VERSION ""

NS_ :

BS_:

BU_: INTERCEPTOR COMMA XXX ECM TCM BCM SHIFTER CLUSTER SRS ABS SAS

BO_ 257 ECM_IMMO: 8 ECM
 SG_ LOCKED : 10|1@0+ (1,0) [0|1] "" XXX
 SG_ UNLOCKED : 11|1@0+ (1,0) [0|1] "" XXX

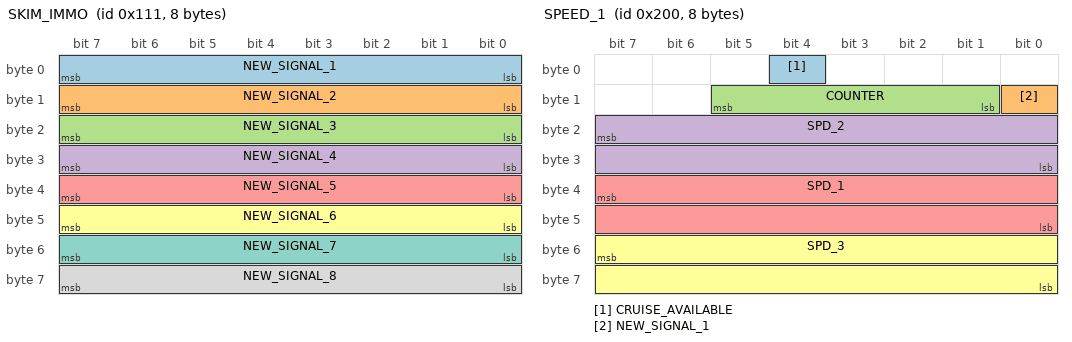
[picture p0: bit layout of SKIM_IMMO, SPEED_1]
BO_ 273 SKIM_IMMO: 8 SKIM
 SG_ NEW_SIGNAL_1 : 7|8@0+ (1,0) [0|255] "" XXX
 SG_ NEW_SIGNAL_2 : 15|8@0+ (1,0) [0|255] "" XXX
 SG_ NEW_SIGNAL_3 : 23|8@0+ (1,0) [0|255] "" XXX
 SG_ NEW_SIGNAL_4 : 31|8@0+ (1,0) [0|255] "" XXX
 SG_ NEW_SIGNAL_5 : 39|8@0+ (1,0) [0|255] "" XXX
 SG_ NEW_SIGNAL_6 : 47|8@0+ (1,0) [0|255] "" XXX
 SG_ NEW_SIGNAL_7 : 55|8@0+ (1,0) [0|255] "" XXX
 SG_ NEW_SIGNAL_8 : 63|8@0+ (1,0) [0|255] "" XXX

BO_ 512 SPEED_1: 8 ABS
 SG_ CRUISE_AVAILABLE : 4|1@0+ (1,0) [0|1] "" XXX
 SG_ NEW_SIGNAL_1 : 8|1@0+ (1,0) [0|1] "" XXX
 SG_ COUNTER : 9|5@1+ (1,0) [0|31] "" XXX
 SG_ SPD_2 : 23|16@0+ (0.059,0) [0|65535] "kph" XXX
 SG_ SPD_1 : 39|16@0+ (0.059,0) [0|65535] "kph" XXX
 SG_ SPD_3 : 55|16@0+ (0.059,0) [0|65535] "kph" XXX

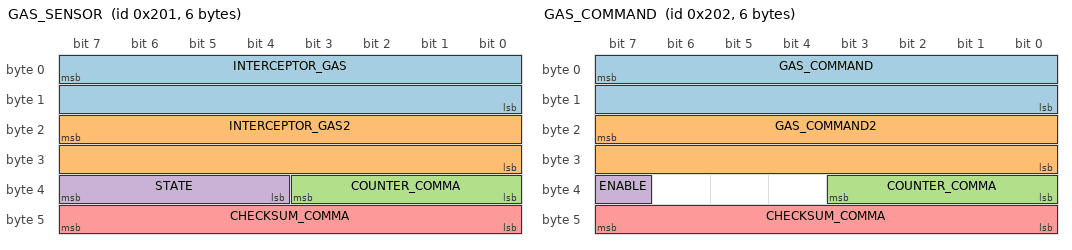
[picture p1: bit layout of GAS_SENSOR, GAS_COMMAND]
BO_ 513 GAS_SENSOR: 6 INTERCEPTOR
 SG_ INTERCEPTOR_GAS : 7|16@0+ (0.098417599,-18.56) [0|1] "" COMMA
 SG_ INTERCEPTOR_GAS2 : 23|16@0+ (0.183585313,-14.79) [0|1] "" COMMA
 SG_ COUNTER_COMMA : 35|4@0+ (1,0) [0|15] "" COMMA
 SG_ STATE : 39|4@0+ (1,0) [0|15] "" COMMA
 SG_ CHECKSUM_COMMA : 47|8@0+ (1,0) [0|255] "" COMMA

BO_ 514 GAS_COMMAND: 6 COMMA
 SG_ GAS_COMMAND : 7|16@0+ (0.098417599,-18.56) [0|1] "" INTERCEPTOR
 SG_ GAS_COMMAND2 : 23|16@0+ (0.183585313,-14.79) [0|1] "" INTERCEPTOR
 SG_ COUNTER_COMMA : 35|4@0+ (1,0) [0|15] "" INTERCEPTOR
 SG_ ENABLE : 39|1@0+ (1,0) [0|1] "" INTERCEPTOR
 SG_ CHECKSUM_COMMA : 47|8@0+ (1,0) [0|255] "" INTERCEPTOR

BO_ 520 NEW_MSG_5: 8 XXX
 SG_ NEW_SIGNAL_4 : 7|16@0+ (1,0) [0|65535] "" XXX
 SG_ NEW_SIGNAL_1 : 23|16@0+ (1,0) [0|65535] "" XXX
 SG_ NEW_SIGNAL_3 : 39|16@0+ (1,0) [0|65535] "" XXX
 SG_ NEW_SIGNAL_2 : 55|18@0+ (1,0) [0|255] "" XXX

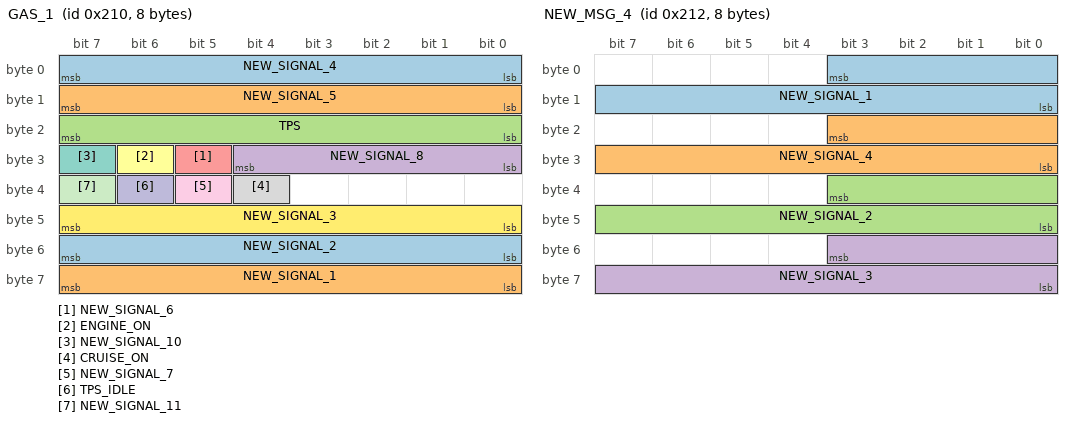
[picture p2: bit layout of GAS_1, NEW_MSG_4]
BO_ 528 GAS_1: 8 ECM
 SG_ NEW_SIGNAL_4 : 7|8@0+ (1,0) [0|1] "" XXX
 SG_ NEW_SIGNAL_5 : 15|8@0+ (1,0) [0|1] "" XXX
 SG_ TPS : 23|8@0+ (1,0) [0|250] "" XXX
 SG_ NEW_SIGNAL_8 : 28|5@0+ (1,0) [0|1] "" XXX
 SG_ NEW_SIGNAL_6 : 29|1@0+ (1,0) [0|1] "" XXX
 SG_ ENGINE_ON : 30|1@0+ (1,0) [0|1] "" XXX
 SG_ NEW_SIGNAL_10 : 31|1@0+ (1,0) [0|1] "" XXX
 SG_ CRUISE_ON : 36|1@0+ (1,0) [0|1] "" XXX
 SG_ NEW_SIGNAL_7 : 37|1@0+ (1,0) [0|1] "" XXX
 SG_ TPS_IDLE : 38|1@0+ (1,0) [0|1] "" XXX
 SG_ NEW_SIGNAL_11 : 39|1@0+ (1,0) [0|1] "" XXX
 SG_ NEW_SIGNAL_3 : 47|8@0+ (1,0) [0|1] "" XXX
 SG_ NEW_SIGNAL_2 : 55|8@0+ (1,0) [0|1] "" XXX
 SG_ NEW_SIGNAL_1 : 63|8@0+ (1,0) [0|1] "" XXX

BO_ 530 NEW_MSG_4: 8 XXX
 SG_ NEW_SIGNAL_1 : 3|12@0+ (1,0) [0|255] "" XXX
 SG_ NEW_SIGNAL_4 : 19|12@0+ (1,0) [0|65535] "" XXX
 SG_ NEW_SIGNAL_2 : 35|12@0+ (1,0) [0|65535] "" XXX
 SG_ NEW_SIGNAL_3 : 51|12@0+ (1,0) [0|15] "" XXX

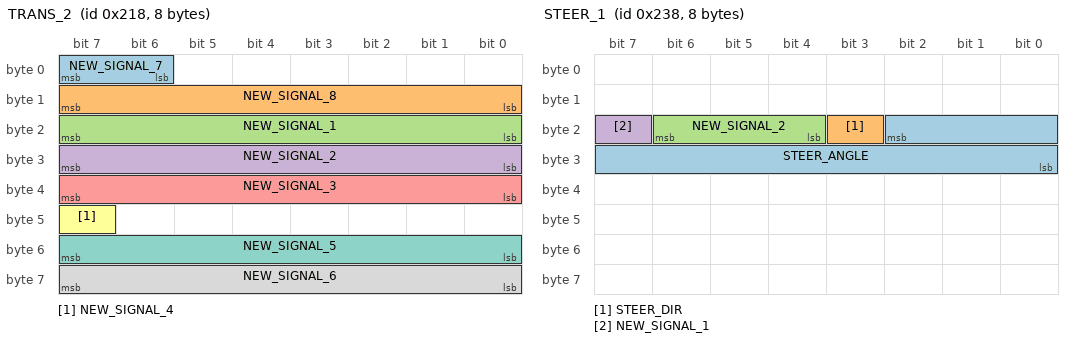
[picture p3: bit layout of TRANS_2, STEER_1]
BO_ 536 TRANS_2: 8 TCM
 SG_ NEW_SIGNAL_7 : 7|2@0+ (1,0) [0|1] "" XXX
 SG_ NEW_SIGNAL_8 : 15|8@0+ (1,0) [0|1] "" XXX
 SG_ NEW_SIGNAL_1 : 23|8@0+ (1,0) [0|255] "" XXX
 SG_ NEW_SIGNAL_2 : 31|8@0+ (1,0) [0|65535] "" XXX
 SG_ NEW_SIGNAL_3 : 39|8@0+ (1,0) [0|255] "" XXX
 SG_ NEW_SIGNAL_4 : 47|1@0+ (1,0) [0|1] "" XXX
 SG_ NEW_SIGNAL_5 : 55|8@0+ (1,0) [0|1] "" XXX
 SG_ NEW_SIGNAL_6 : 63|8@0+ (1,0) [0|1] "" XXX

BO_ 560 SHIFTER: 1 SHIFTER
 SG_ SHIFTER M : 3|4@0+ (1,0) [0|1] "" XXX
 SG_ WINTER : 7|1@0+ (1,0) [0|1] "" XXX

BO_ 568 STEER_1: 8 SAS
 SG_ STEER_ANGLE : 18|11@0+ (0.5,0) [0|65535] "" XXX
 SG_ STEER_DIR : 19|1@0+ (1,0) [0|1] "" XXX
 SG_ NEW_SIGNAL_2 : 22|3@0+ (1,0) [0|7] "" XXX
 SG_ NEW_SIGNAL_1 : 23|1@0+ (1,0) [0|1] "" XXX

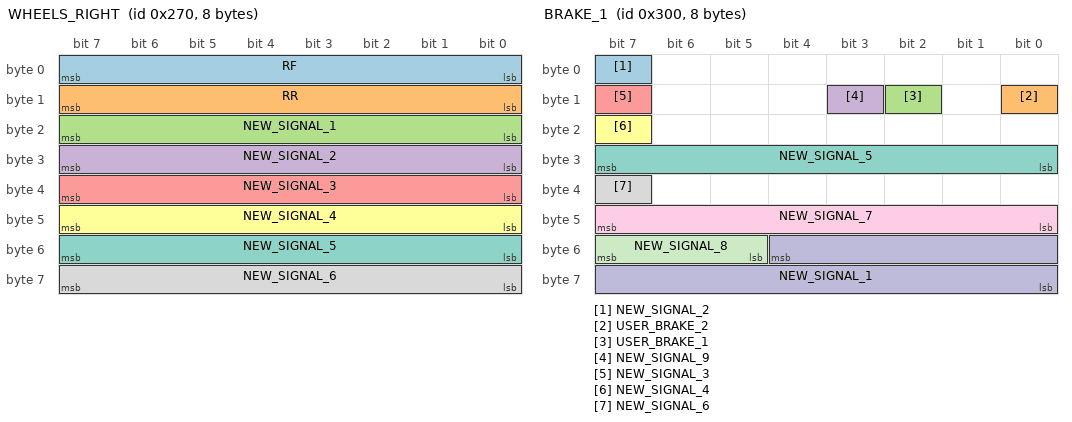
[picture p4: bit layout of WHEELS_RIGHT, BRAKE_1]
BO_ 624 WHEELS_RIGHT: 8 ABS
 SG_ RF : 7|8@0+ (1,0) [0|255] "" XXX
 SG_ RR : 15|8@0+ (1,0) [0|257] "" XXX
 SG_ NEW_SIGNAL_1 : 23|8@0+ (1,0) [0|1] "" XXX
 SG_ NEW_SIGNAL_2 : 31|8@0+ (1,0) [0|1] "" XXX
 SG_ NEW_SIGNAL_3 : 39|8@0+ (1,0) [0|1] "" XXX
 SG_ NEW_SIGNAL_4 : 47|8@0+ (1,0) [0|1] "" XXX
 SG_ NEW_SIGNAL_5 : 55|8@0+ (1,0) [0|1] "" XXX
 SG_ NEW_SIGNAL_6 : 63|8@0+ (1,0) [0|1] "" XXX

BO_ 768 BRAKE_1: 8 ABS
 SG_ NEW_SIGNAL_2 : 7|1@0+ (1,0) [0|1] "" XXX
 SG_ USER_BRAKE_2 : 8|1@0+ (1,0) [0|1] "" XXX
 SG_ USER_BRAKE_1 : 10|1@1+ (1,0) [0|7] "" XXX
 SG_ NEW_SIGNAL_9 : 11|1@0+ (1,0) [0|1] "" XXX
 SG_ NEW_SIGNAL_3 : 15|1@0+ (1,0) [0|1] "" XXX
 SG_ NEW_SIGNAL_4 : 23|1@0+ (1,0) [0|1] "" XXX
 SG_ NEW_SIGNAL_5 : 31|8@0+ (1,0) [0|1] "" XXX
 SG_ NEW_SIGNAL_6 : 39|1@0+ (1,0) [0|1] "" XXX
 SG_ NEW_SIGNAL_7 : 47|8@0+ (1,0) [0|1] "" XXX
 SG_ NEW_SIGNAL_1 : 52|13@0- (1,0) [0|65535] "" XXX
 SG_ NEW_SIGNAL_8 : 55|3@0+ (1,0) [0|1] "" XXX

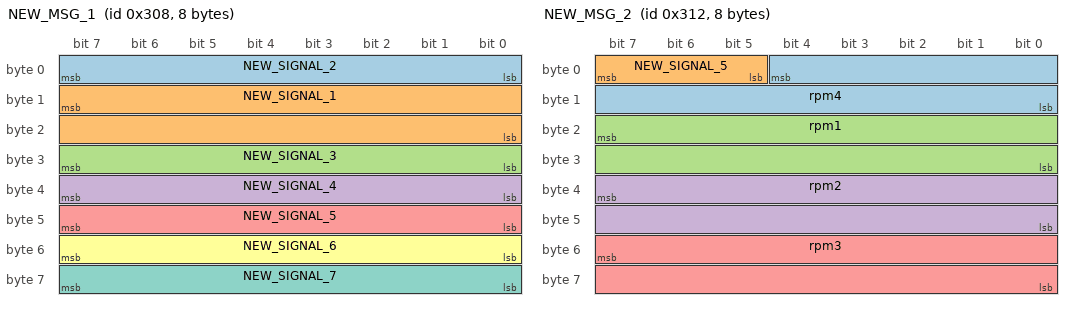
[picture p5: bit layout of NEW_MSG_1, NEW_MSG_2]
BO_ 776 NEW_MSG_1: 8 XXX
 SG_ NEW_SIGNAL_2 : 7|8@0+ (1,0) [0|1] "" XXX
 SG_ NEW_SIGNAL_1 : 15|16@0+ (1,0) [0|65535] "" XXX
 SG_ NEW_SIGNAL_3 : 31|8@0+ (1,0) [0|1] "" XXX
 SG_ NEW_SIGNAL_4 : 39|8@0+ (1,0) [0|1] "" XXX
 SG_ NEW_SIGNAL_5 : 47|8@0+ (1,0) [0|1] "" XXX
 SG_ NEW_SIGNAL_6 : 55|8@0+ (1,0) [0|1] "" XXX
 SG_ NEW_SIGNAL_7 : 63|8@0+ (1,0) [0|1] "" XXX

BO_ 786 NEW_MSG_2: 8 XXX
 SG_ rpm4 : 4|13@0- (1,0) [0|65535] "" XXX
 SG_ NEW_SIGNAL_5 : 7|3@0+ (1,0) [0|1] "" XXX
 SG_ rpm1 : 23|16@0+ (1,0) [0|65535] "" XXX
 SG_ rpm2 : 39|16@0+ (1,0) [0|65535] "" XXX
 SG_ rpm3 : 55|16@0+ (-1,0) [0|65535] "" XXX

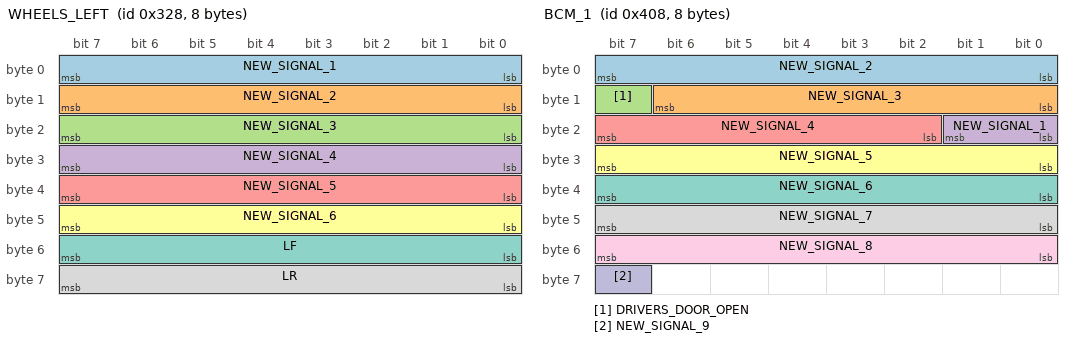
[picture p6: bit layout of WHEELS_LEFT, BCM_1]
BO_ 808 WHEELS_LEFT: 8 ABS
 SG_ NEW_SIGNAL_1 : 7|8@0+ (1,0) [0|1] "" XXX
 SG_ NEW_SIGNAL_2 : 15|8@0+ (1,0) [0|1] "" XXX
 SG_ NEW_SIGNAL_3 : 23|8@0+ (1,0) [0|1] "" XXX
 SG_ NEW_SIGNAL_4 : 31|8@0+ (1,0) [0|1] "" XXX
 SG_ NEW_SIGNAL_5 : 39|8@0+ (1,0) [0|1] "" XXX
 SG_ NEW_SIGNAL_6 : 47|8@0+ (1,0) [0|1] "" XXX
 SG_ LF : 55|8@0+ (1,0) [0|255] "" XXX
 SG_ LR : 63|8@0+ (1,0) [0|255] "" XXX

BO_ 824 TRANS_3: 8 TCM
 SG_ NEW_SIGNAL_9 : 7|8@0+ (1,0) [0|255] "" XXX
 SG_ NEW_SIGNAL_3 : 15|8@0+ (1,0) [0|1] "" XXX
 SG_ NEW_SIGNAL_4 : 23|8@0+ (1,0) [0|1] "" XXX
 SG_ NEW_SIGNAL_5 : 31|8@0+ (1,0) [0|1] "" XXX
 SG_ NEW_SIGNAL_6 : 39|8@0+ (1,0) [0|1] "" XXX
 SG_ NEW_SIGNAL_7 : 47|8@0+ (1,0) [0|1] "" XXX
 SG_ NEW_SIGNAL_1 : 51|14@0- (1,0) [0|65535] "" XXX
 SG_ NEW_SIGNAL_8 : 55|4@0+ (1,0) [0|1] "" XXX

BO_ 1032 BCM_1: 8 BCM
 SG_ NEW_SIGNAL_2 : 7|8@0+ (1,0) [0|1] "" XXX
 SG_ NEW_SIGNAL_3 : 14|7@0+ (1,0) [0|1] "" XXX
 SG_ DRIVERS_DOOR_OPEN : 15|1@0+ (1,0) [0|1] "" XXX
 SG_ NEW_SIGNAL_1 : 16|2@1+ (1,0) [0|3] "" XXX
 SG_ NEW_SIGNAL_4 : 23|6@0+ (1,0) [0|1] "" XXX
 SG_ NEW_SIGNAL_5 : 31|8@0+ (1,0) [0|1] "" XXX
 SG_ NEW_SIGNAL_6 : 39|8@0+ (1,0) [0|1] "" XXX
 SG_ NEW_SIGNAL_7 : 47|8@0+ (1,0) [0|1] "" XXX
 SG_ NEW_SIGNAL_8 : 55|8@0+ (1,0) [0|1] "" XXX
 SG_ NEW_SIGNAL_9 : 63|1@0+ (1,0) [0|1] "" XXX

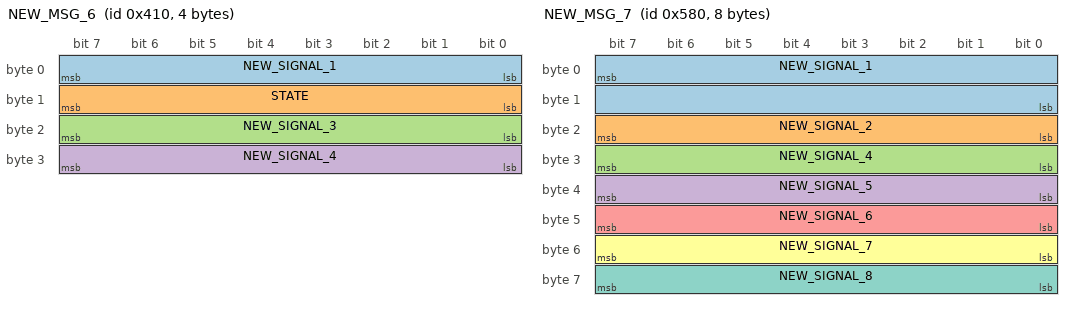
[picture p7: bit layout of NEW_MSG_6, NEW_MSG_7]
BO_ 1040 NEW_MSG_6: 4 XXX
 SG_ NEW_SIGNAL_1 : 7|8@0+ (1,0) [0|1] "" XXX
 SG_ STATE : 15|8@0+ (1,0) [0|1] "" XXX
 SG_ NEW_SIGNAL_3 : 23|8@0+ (1,0) [0|1] "" XXX
 SG_ NEW_SIGNAL_4 : 31|8@0+ (1,0) [0|1] "" XXX

BO_ 1048 TRANS_1: 8 TCM
 SG_ GEAR_ASCII : 7|8@0+ (1,0) [0|1] "" XXX
 SG_ MODE_ASCII : 15|8@0+ (1,0) [0|255] "" XXX
 SG_ NEW_SIGNAL_4 : 23|8@0+ (1,0) [0|255] "" XXX
 SG_ NEW_SIGNAL_6 : 31|8@0+ (1,0) [0|1] "" XXX
 SG_ NEW_SIGNAL_5 : 39|8@0+ (1,0) [0|1] "" XXX
 SG_ NEW_SIGNAL_1 : 47|8@0+ (1,0) [0|16777215] "" XXX
 SG_ NEW_SIGNAL_2 : 48|11@0+ (1,0) [0|255] "" XXX
 SG_ NEW_SIGNAL_3 : 53|1@0+ (1,0) [0|255] "" XXX
 SG_ NEW_SIGNAL_7 : 54|1@1+ (1,0) [0|3] "" XXX

BO_ 1408 NEW_MSG_7: 8 XXX
 SG_ NEW_SIGNAL_1 : 7|16@0+ (1,0) [0|1] "" XXX
 SG_ NEW_SIGNAL_2 : 23|8@0+ (1,0) [0|1] "" XXX
 SG_ NEW_SIGNAL_4 : 31|8@0+ (1,0) [0|1] "" XXX
 SG_ NEW_SIGNAL_5 : 39|8@0+ (1,0) [0|1] "" XXX
 SG_ NEW_SIGNAL_6 : 47|8@0+ (1,0) [0|1] "" XXX
 SG_ NEW_SIGNAL_7 : 55|8@0+ (1,0) [0|1] "" XXX
 SG_ NEW_SIGNAL_8 : 63|8@0+ (1,0) [0|1] "" XXX

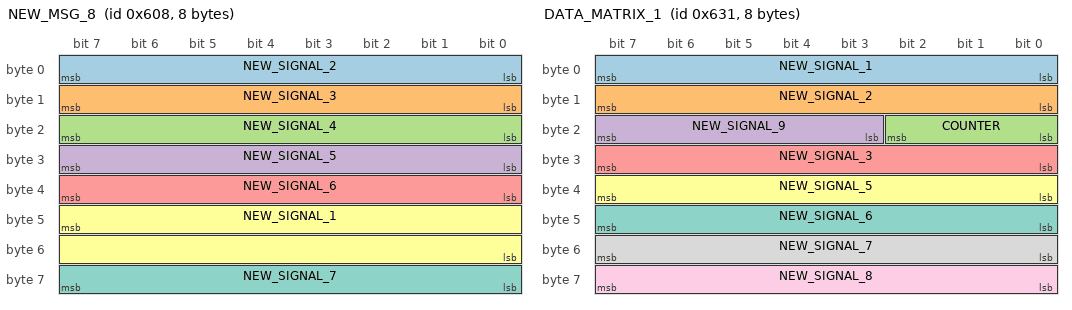
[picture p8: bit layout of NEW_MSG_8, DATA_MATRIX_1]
BO_ 1544 NEW_MSG_8: 8 XXX
 SG_ NEW_SIGNAL_2 : 7|8@0+ (1,0) [0|1] "" XXX
 SG_ NEW_SIGNAL_3 : 15|8@0+ (1,0) [0|1] "" XXX
 SG_ NEW_SIGNAL_4 : 23|8@0+ (1,0) [0|1] "" XXX
 SG_ NEW_SIGNAL_5 : 31|8@0+ (1,0) [0|1] "" XXX
 SG_ NEW_SIGNAL_6 : 39|8@0+ (1,0) [0|1] "" XXX
 SG_ NEW_SIGNAL_1 : 47|16@0- (1,0) [0|1] "" XXX
 SG_ NEW_SIGNAL_7 : 63|8@0+ (1,0) [0|1] "" XXX

BO_ 1585 DATA_MATRIX_1: 8 XXX
 SG_ NEW_SIGNAL_1 : 7|8@0+ (1,0) [0|1] "" XXX
 SG_ NEW_SIGNAL_2 : 15|8@0+ (1,0) [0|1] "" XXX
 SG_ COUNTER : 18|3@0+ (1,0) [0|1] "" XXX
 SG_ NEW_SIGNAL_9 : 23|5@0+ (1,0) [0|31] "" XXX
 SG_ NEW_SIGNAL_3 : 31|8@0+ (1,0) [0|255] "" XXX
 SG_ NEW_SIGNAL_5 : 39|8@0+ (1,0) [0|1] "" XXX
 SG_ NEW_SIGNAL_6 : 47|8@0+ (1,0) [0|1] "" XXX
 SG_ NEW_SIGNAL_7 : 55|8@0+ (1,0) [0|1] "" XXX
 SG_ NEW_SIGNAL_8 : 63|8@0+ (1,0) [0|1] "" XXX

VAL_ 560 SHIFTER 8 "PARK" 7 "REVERSE" 6 "NEUTRAL" 5 "DRIVE" 11 "MID_DRIVE_NEUTRAL" 12 "NEUTRAL_REVERSE" 23 "PARK INTERLOCK A" 29 "PARK INTERLOCK B" 24 "PARK INTERLOCK C" 10 "AUTOSTICK_MINUS" 9 "AUTOSTICK_PLUS";
